# BL808 register map
File version: 0.1
Bouffalo Labs BL808
Registers are access not given, no defined reset value unless marked. A register's access mark holds for its fields unless they carry their own. Offsets are from the block's base; lines under a group give offsets from that group; [hi:lo] are bit positions; {n}, {i} and the like mark numbered series; 'fields as' and 'values as' point back to an identical list; <NAME> marks a mode.

## Memory map
0x02007200 USB
0x20000000 GLB
0x20002000 ADC
0x20002040 DAC
0x20003000 SEC_DBG
0x20004000 SEC_ENG
0x20008000 CCI
0x20009000 MCU_MISC
0x2000A000 UART0
0x2000A100 UART1
0x2000A200 SPI0
0x2000A300 I2C0
0x2000A400 PWM
0x2000A500 TIMER0
0x2000A600 IR
0x2000A900 I2C1
0x2000AB00 I2S
0x2000AD00 LZ4D
0x2000B000 SF_CTRL
0x2000C000 DMA0
0x2000E000 PDS
0x2000F000 AON
0x2000F004 LowPower
0x20052000 pSRAM
0x20055000 AUDIO
0x20056000 eFuse_Ctrl
0x20056000 eFuse_Data0
0x20056000 eFuse_Data1
0x20060000 SDH
0x20070000 EMAC
0x20071000 DMA1
0x30000000 MM_MISC
0x30001000 DMA2
0x30002000 UART3
0x30003000 I2C2
0x30004000 I2C3
0x30005000 IPC2
0x30006000 DMA2D
0x30007000 MM_GLB_CLK_RST
0x30008000 SPI1
0x30009000 TIMER1
0x3000C000 PDM0
0x3000D000 PDM1
0x30010000 DSP2_MISC
0x30011000 DSP2
{0x30012000+0x100*n} DVP{n} (n=0..7)
0x30012A00 AXI_CTRL_NR3d
0x30012B00 OSD_PROBE
0x30013000 OSD_A_BLEND_LAYER0
0x30013100 OSD_A_BLEND_LAYER1
0x30013200 OSD_A_BLEND_LAYER2
0x30013300 OSD_A_BLEND_LAYER3
0x30013400 OSD_A_DRAW_LAYER_L
0x30013504 OSD_A_DRAW_LAYER_H
0x30014000 OSD_B_BLEND_LAYER0
0x30014100 OSD_B_BLEND_LAYER1
0x30014400 OSD_B_DRAW_LAYER_L
0x30015000 OSD_DP_BLEND_LAYER0
0x30015100 OSD_DP_BLEND_LAYER1
0x30015200 OSD_DP_BLEND_LAYER2
0x30015300 OSD_DP_BLEND_LAYER3
0x30015400 OSD_DP_DRAW_LAYER_L
0x30015504 OSD_DP_DRAW_LAYER_H
0x30016000 DSP2_AWB3_BASE
0x3001A000 CSI
0x3001A000 MIPI
0x3001A100 DSI
0x3001B000 DBI
0x30020000 CODEC_MISC
0x30021000 MJPEG_Q
0x30021000 MJPEG
0x30023000 MJDEC
0x2000A8000 IPC0
0x2000A8400 IPC1

## MJDEC
Base 0x30023000
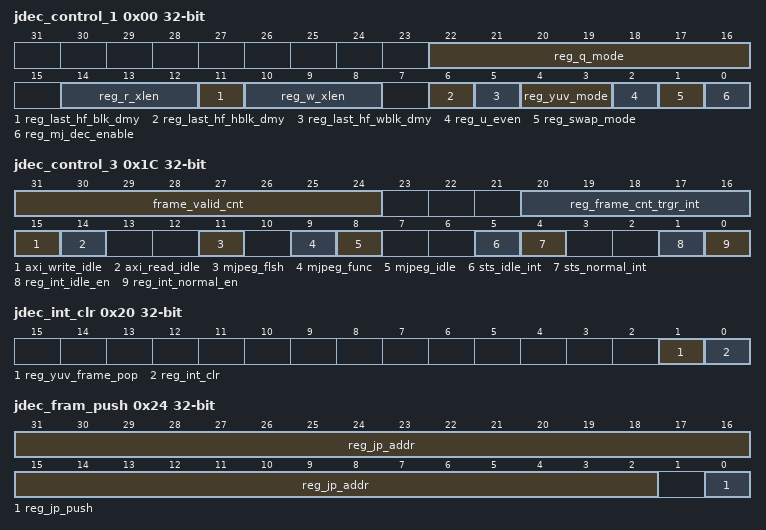
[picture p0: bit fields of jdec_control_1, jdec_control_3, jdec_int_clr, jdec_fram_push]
0x00 jdec_control_1
  [22:16] reg_q_mode rw — Quantization Selection 1-75 : Q table selection Others : Q100(Lossless)
  [14:12] reg_r_xlen rw — AXI read burst length setting 3'd0-Single / 3'd1-INCR4 / 3'd2-INCR8 3'd3 - INCR16 / Others - RSVD
  [11] reg_last_hf_blk_dmy rw — JDEC last half block with dummy data 8'h80
  [10:8] reg_w_xlen rw — AXI write burst length setting 3'd0-Single / 3'd1-INCR4 / 3'd2-INCR8 3'd3 - INCR16 / Others - RSVD
  [6] reg_last_hf_hblk_dmy rw — JDEC last half vertical block drop
  [5] reg_last_hf_wblk_dmy rw — JDEC last half horizational block drop
  [4:3] reg_yuv_mode rw — YUV format setting 2'd0 : YUV420 Planar 2'd1 : YUV400 grey scale 2'd2 : YUV422 Planar
  [2] reg_u_even rw — 1'b0 - U is odd byte of UV frame / V is even byte of UV frame 1'b1 - U is even byte of UV frame / V is odd byte of UV frame
  [1] reg_swap_mode rw — JDEC YUV Memory swap mode
  [0] reg_mj_dec_enable rw — JDEC Enable
0x08 jdec_yy_frame_addr rw
  [31:0] reg_yy_addr_start — Memory start address of Y frame
0x0C jdec_uv_frame_addr rw
  [31:0] reg_uv_addr_start — Memory start address of UV frame
0x1C jdec_control_3
  [31:24] frame_valid_cnt ro — Frame count valid in status
  [20:16] reg_frame_cnt_trgr_int rw — Frame threshold to issue interrupt
  [15] axi_write_idle ro — AXI write bus idle state
  [14] axi_read_idle ro — AXI read bus idle state
  [11] mjpeg_flsh ro — MJPEG in flush state
  [9] mjpeg_func ro — MJPEG in HW function state
  [8] mjpeg_idle ro — MJPEG in idle state
  [5] sts_idle_int ro — Normal Write interrupt status
  [4] sts_normal_int ro — Normal Write interrupt status
  [1] reg_int_idle_en rw — Back idle interrupt enable
  [0] reg_int_normal_en rw — Normal Write interrupt enable
0x20 jdec_int_clr
  [1] reg_yuv_frame_pop write-once — Wrire this bit with 1'b1 to pop yuv frame cnt
  [0] reg_int_clr write-once — Wrire this bit with 1'b1 to trigger interrupt clear
0x24 jdec_fram_push
  [31:2] reg_jp_addr rw — JPEG Start Addr
  [0] reg_jp_push write-once — Wrire this bit with 1'b1 to push jpg frame
0x28 jdec_fram_sts
  [4:0] jp_frame_cnt ro — JPEG FIFO frame cnt
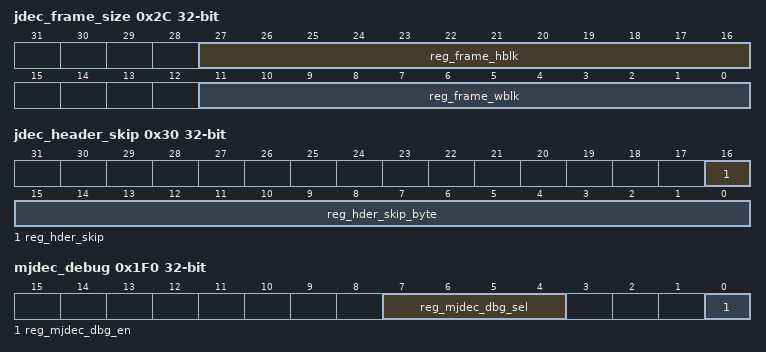
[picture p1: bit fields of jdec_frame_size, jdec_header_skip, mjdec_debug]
0x2C jdec_frame_size
  [27:16] reg_frame_hblk rw — Frame total vertical block count
  [11:0] reg_frame_wblk rw — Frame total horizational block count
0x30 jdec_header_skip
  [16] reg_hder_skip rw — Skip JPEG stream header enable
  [15:0] reg_hder_skip_byte rw — Skip JPEG stream header byte
{0x40+4i} jp_addr{i} ro (i=0..7)
  [31:0] jp_addr_{i} — JPEG PIC {i} Start address
0x60 jp_addr_8 ro
  [31:0] jp_addr_8 — JPEG PIC 8 Start address
0x64 jp_addr_9 ro
  [31:0] jp_addr_9 — JPEG PIC 9 Start address
0x68 jp_addr_a ro
  [31:0] jp_addr_a — JPEG PIC A Start address
0x6C jp_addr_b ro
  [31:0] jp_addr_b — JPEG PIC B Start address
0x70 jp_addr_c ro
  [31:0] jp_addr_c — JPEG PIC C Start address
0x74 jp_addr_d ro
  [31:0] jp_addr_d — JPEG PIC D Start address
0x78 jp_addr_e ro
  [31:0] jp_addr_e — JPEG PIC E Start address
0x7C jp_addr_f ro
  [31:0] jp_addr_f — JPEG PIC F Start address
0x1F0 mjdec_debug
  [7:4] reg_mjdec_dbg_sel rw — MJPEG debgu flag selection
  [0] reg_mjdec_dbg_en rw — MJPEG debgu flag enable
0x1FC mjdec_dummy_reg rw
  [31:0] jdec_dummy_reg — Dummy R/W register
